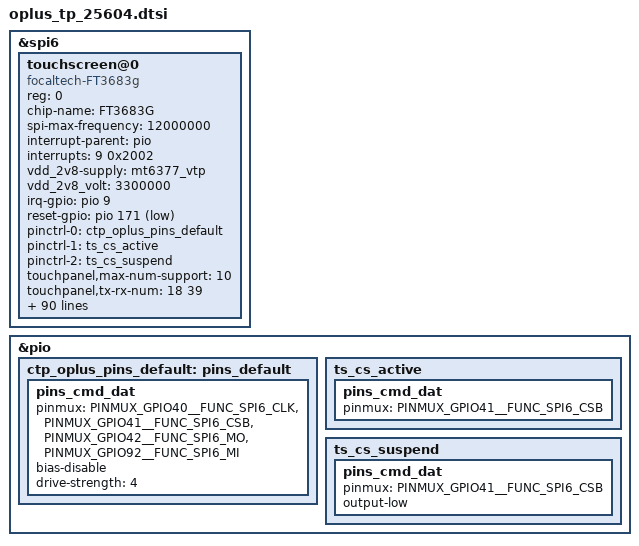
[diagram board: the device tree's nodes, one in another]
&spi6 {
    status = "okay";
    #address-cells = <1>;
    #size-cells = <0>;

    touchscreen@0{
        compatible = "focaltech-FT3683g";
        reg = <0>;
        chip-name = "FT3683G";
        status = "ok";

        spi-max-frequency = <12000000>;
        /* Interrupt && Irq-gpio */
        interrupt-parent = <&pio>;
        interrupts = <9 0x2002>;

        /* Power Config */
        vdd_2v8-supply  = <&mt6377_vtp>;
        vdd_2v8_volt = <3300000>;
        //enable1v8_gpio = <&pio 22 0x1>;
        //vcc_1v8-supply  = <&mt6369_vtp>;
        //vcc_1v8_volt = <1800000>;

        /* Other HW Resource */

        irq-gpio = <&pio 9 0x2002>;
        reset-gpio = <&pio 171 0x1>;

		pinctrl-names = "default", "pin_cs_high","pin_cs_low";
		pinctrl-0 = <&ctp_oplus_pins_default>;
		pinctrl-1 = <&ts_cs_active>;
		pinctrl-2 = <&ts_cs_suspend>;

        touchpanel,max-num-support = <10>;
        touchpanel,tx-rx-num = <18 39>;
        touchpanel,panel-coords = <17280 37952>;
        touchpanel,display-coords = <1080 2372>;
        touchpanel,touchmajor-limit = <128 216>;
        touchpanel,smooth-level = <0 110 115 120 140 155>;
        touchpanel,smooth-level-charging = <0 110 115 120 140 155>;
        touchpanel,sensitive-level = <0 19 16 13 11 10>;
        touchpanel,high-frame-rate-time = <60>;
        touchpanel,single-optimized-time = <8>;

        panel_type = <3>;
        // type of tp_dev ,TP-BOE = 3;  TP-Tianma = 7, VXN = 18;
        firmware_name = "0xAE113";
        platform_support_project = <25604 25668 25669 25678 25679>;
        platform_support_project_dir = <25604 25604 25604 25604 25604>;
        platform_support_project_commandline = "panel_ae112_p_3_a0025_dsi_vdo";

        prevention,curved_screen_V2;
        prevention,grip_disable_level = <6>;
        prevention,updelay_time_ms = <30>;
        prevention,makeup_cnt_weight = <4 1 2 2 2>;
        prevention,large_corner_range = <640 1581>;
        prevention,large_corner_judge_condition = <500 300 600 7 7>;
        prevention,trx_reject_condition = <9 6 7>;
        prevention,trx_strict_reject_condition = <8 5 6>;
        prevention,large_judge_time_ms = <500 50 30>;
        prevention,large_exit_condition = <8 8 2>;
        prevention,single_channel_width = <160 160>;
        prevention,normal_tap_condition = <10 350>;
        prevention,long_edge_condition = <200 80 180 80>;
        prevention,long_strict_edge_condition = <160 60>;
        prevention,long_fingerhold_condition = <50 6 4 4>;
        prevention,short_edge_condition = <200 80 180 80>;
        prevention,short_strict_edge_condition = <160 60>;
        prevention,large_strict_exit_condition = <4 4>;
        prevention,top_corner_config = <280 800 280>;
        prevention,edge_swipe_config = <160 600>;

        prevention,curved_screen_V4;
        prevention,long_eliminate_point_type = <2 17280 12650 140 12864 300 1>;
        prevention,long_fingerhold_condition2 = <370 800 0 0>;
        prevention,top_corner_config2 = <3 80 420 600 0>;
        prevention,hor_long_top_corner_config = <152 1054 0 0>;
        prevention,top_middle_config = <5760 527 527 0>;
        prevention,corner_eliminate_point_type = <0 640 1054 1>;
        prevention,finger_hold_differ_size = <1 0 240 300>;
        prevention,finger_hold_max_rx_exit_distance = <5 240 1600>;
        prevention,max_rx_exit_distance = <1 5 150 240 1600>;
        prevention,dynamic_finger_hold_exit_distance = <1 240 1600 360>;
        prevention,edge_sliding_matched_support = <1 150 3 0>;

        //grip v4.2 reclining mode -> not support in Camry
        /*prevention,reclining_mode_support = <1>;
        prevention,long_eliminate_point_type_recli = <2 8640 6400 240 19200 500 0>;
        prevention,finger_hold_differ_size_recli = <1 0 240 400>;
        prevention,finger_hold_max_rx_exit_distance_recli = <4 240 1600>;
        prevention,max_rx_exit_distance_recli = <1 4 100 240 1600>;
        prevention,dynamic_finger_hold_exit_distance_recli = <1 240 1600 360>;
        prevention,edge_sliding_matched_support_recli = <1 200 3 0>;
        prevention,long_edge_condition_recli = <160 80 120 80>;*/

        /* SW Support Feature Control */
        health_monitor_support;
        black_gesture_support;
        kernel_grip_support;
        charger_pump_support;
        //lcd_tp_refresh_support;
        fw_update_app_support;
        smart_gesture_support;
        game_switch_support;
        report_flow_unlock_support;
        fingerprint_underscreen_support;
        pressure_report_support;
        //report_rate_white_list_support;
        auto_test_force_pass_support;
        snr_read_support;
        //high_resolution_support;
        screenoff_fingerprint_info_support;
        irq_need_dev_resume_ok;
        sportify_aod_gesture_support;
        black_gesture_indep_support;
        thermal_detect_support;
        exception_upload_support;
        tp_data_record_support;
        palm_to_sleep_support;
        glove_mode_v2_support;
        freq_hop_simulate_support;
        //fw_edge_limit_support;
        temperature_detect_support;
        temperature_detect_shellback_support;
        disable_touch_event_support;
        report_rate_white_list_support;
        aiunit_game_info_support;
        diaphragm_touch_support;
        waterproof_support;
        /*
            *Virtual Key Config:
            *1:touchpanel,button-type: <virtualkey_type  supportted_button-map>
            *virtualkey_type:
            *Type 1: using board_properties
            *Type 2: using same IC (button zone&& touch zone are seprate)
            *Type 3: using diffrent IC (button zone&& touch zone are seprate)
            *Type 4: No need of virtual key process
            *supportted_button-map:select|menu|home|back
            *
            *2:touchpanel,button-map
            *type (X1,Y1)(X2,Y2)(X3,Y3)(Width_X,Hight_Y)--Only when button-type is 0
        */
        touchpanel,button-type = <4>;
        touchpanel.button-TRx = <0 0>;
    };
};

&pio {
	ctp_oplus_pins_default: pins_default {
		pins_cmd_dat {
			pinmux = <PINMUX_GPIO40__FUNC_SPI6_CLK>,
					<PINMUX_GPIO41__FUNC_SPI6_CSB>,
					<PINMUX_GPIO42__FUNC_SPI6_MO>,
					<PINMUX_GPIO92__FUNC_SPI6_MI>;
			bias-disable;
			drive-strength = <4>;
		};
	};
	ts_cs_active: ts_cs_active {
		pins_cmd_dat {
			pinmux = <PINMUX_GPIO41__FUNC_SPI6_CSB>;
		};
	};
	ts_cs_suspend: ts_cs_suspend {
		pins_cmd_dat {
			pinmux = <PINMUX_GPIO41__FUNC_SPI6_CSB>;
			output-low;
		};
	};
};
